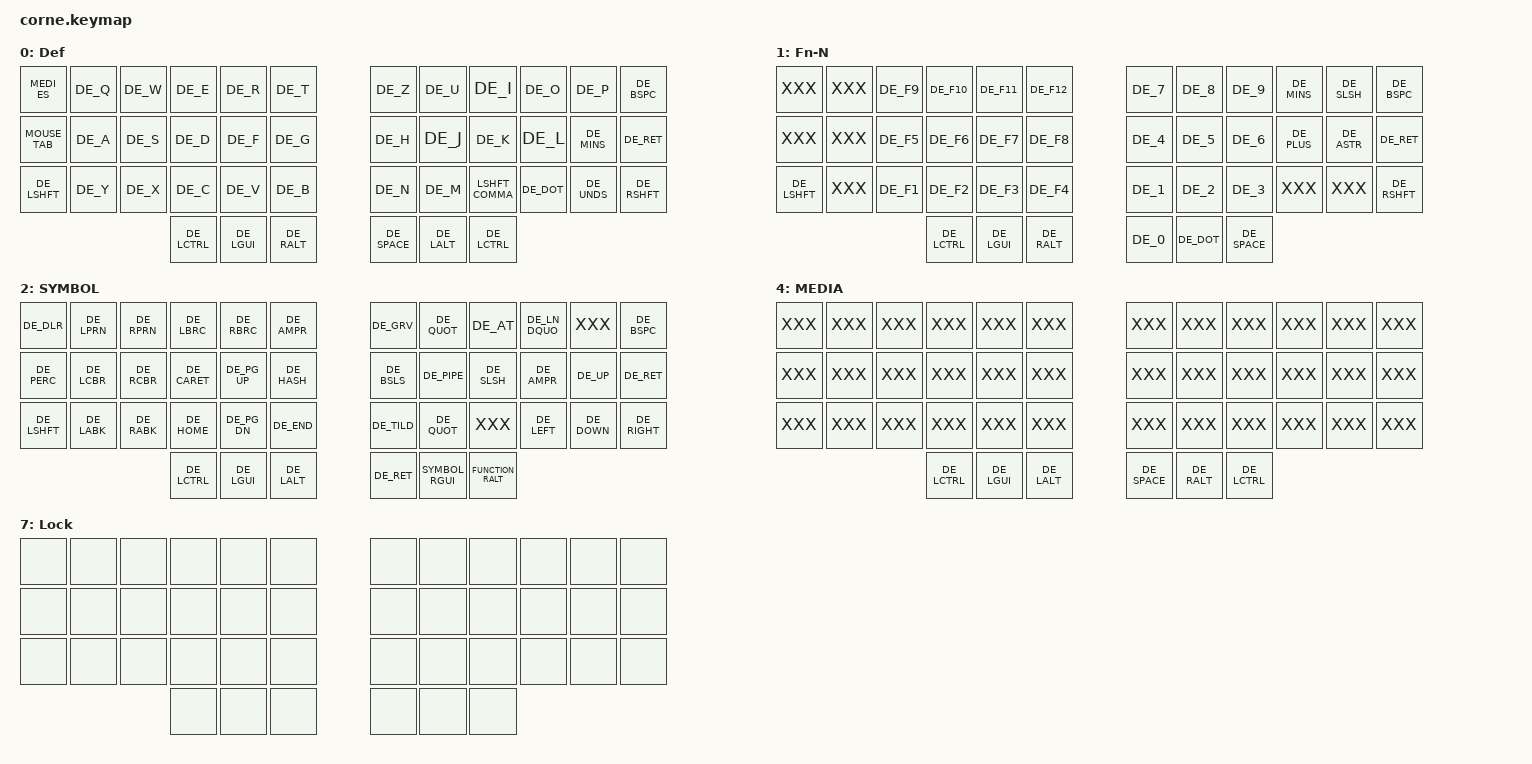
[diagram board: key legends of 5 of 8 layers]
/* ========================================
FileName: corne.keymap
Date: 15:17 23.September.2022
Author: Marcos Chow Castro
Email: mctechnology170318@gmail.com
GitHub: https://github.com/mctechnology17
Brief: keymap for the wireless corne keyboard
                             ╔═╦═╦═╗
                      ╔════╗ ║║║║║╔╝
                      ║╔╗╔╗║ ║║║║║╚╗
                      ╚╝║║╚╝ ║╠═╩╩═╝
                        ║╠═╦═╣╚╦═╦╦═╦╗╔═╦═╦╦╗
                        ║║╩╣═╣║║║║║╬║╚╣╬║╬║║║
                        ╚╩═╩═╩╩╩╩═╩═╩═╩═╬╗╠╗║
                                        ╚═╩═╝
Copyright (c) 2020 The ZMK Contributors
SPDX-License-Identifier: MIT
========================================= */
#define HOST_OS 2
// ### include {{{
#include <behaviors.dtsi>
#include <dt-bindings/zmk/keys.h>
#include <dt-bindings/zmk/bt.h>
#include <dt-bindings/zmk/outputs.h>
#include <dt-bindings/zmk/ext_power.h>
#include <dt-bindings/led/led.h>
#include <dt-bindings/zmk/backlight.h>
#include <dt-bindings/zmk/rgb.h>
#include <dt-bindings/zmk/reset.h>
#include "keymap_german_mac_iso_zmk.h"
#include "keypos_42keys.h"
#include "config_zmk.h"
#include "mouse.dtsi"

&led_strip {
    chain-length = <27>;
};

// }}}
/ {
// ### macros {{{
   macros {
      #include "macros.dtsi"
   };
// }}}

/*                                      42 KEY MATRIX / LAYOUT MAPPING

  ╭────────────────────────┬────────────────────────╮ ╭─────────────────────────┬─────────────────────────╮
  │  0   1   2   3   4   5 │  6   7   8   9  10  11 │ │ LT5 LT4 LT3 LT2 LT1 LT0 │ RT0 RT1 RT2 RT3 RT4 RT5 │
  │ 12  13  14  15  16  17 │ 18  19  20  21  22  23 │ │ LM5 LM4 LM3 LM2 LM1 LM0 │ RM0 RM1 RM2 RM3 RM4 RM5 │
  │ 24  25  26  27  28  29 │ 30  31  32  33  34  35 │ │ LB5 LB4 LB3 LB2 LB1 LB0 │ RB0 RB1 RB2 RB3 RB4 RB5 │
  ╰───────────╮ 36  37  38 │ 39  40  41 ╭───────────╯ ╰───────────╮ LH2 LH1 LH0 │ RH0 RH1 RH2 ╭───────────╯
              ╰────────────┴────────────╯                         ╰─────────────┴─────────────╯             */

// ### combos {{{
combos {
    compatible = "zmk,combos";
    unlock { bindings = <&to DEFAULT>; key-positions = <LT5 LH0 RH0 RT5>; layers = <LOCK>; };
    lock { bindings = <&to LOCK>; key-positions = <LT5 RH0>; layers = <LX_>; };
    CO_symbol { bindings = <&to SYMBOL>; key-positions = <22 23>; layers = <DEFAULT NUMBER MOUSE>; };
    CO_FnN { bindings = <&to NUMBER>; key-positions = <10 11>; layers = <DEFAULT SYMBOL MOUSE>; };
    MO_FnN { bindings = <&mo NUMBER>; key-positions = <0 1>; layers = <DEFAULT SYMBOL MOUSE>; };
    MO_symbol { bindings = <&mo SYMBOL>; key-positions = <12 13>; layers = <DEFAULT NUMBER MOUSE>; };
    CO_Def { bindings = <&to DEFAULT>; key-positions = <34 35>; layers = <SYMBOL NUMBER MOUSE>; };
    CO_Mou { bindings = <&to MOUSE>; key-positions = <6 8>; layers = <DEFAULT SYMBOL NUMBER>; };
    CO_AT { bindings = <&kp LBKT>; key-positions = <39 40 41>; };

    CO_UP { bindings = <&kp UP>; key-positions = <9 21>; };
    CO_LEFT { bindings = <&kp LEFT>; key-positions = <20 21>; };
    CO_DOWN { bindings = <&kp DOWN>; key-positions = <21 33>; };
    CO_RIGHT { bindings = <&kp RIGHT>; key-positions = <21 22>; };

    CO_PAGEUP { bindings = <&kp PG_UP>; key-positions = <10 22>; };
    CO_PAGEDOWN { bindings = <&kp PG_DN>; key-positions = <22 34>; };
    CO_HOME { bindings = <&kp HOME>; key-positions = <8 20>; };
    CO_END { bindings = <&kp END>; key-positions = <20 32>; };

    CO_PreScr { bindings = <&kp PRINTSCREEN>; key-positions = <36 37 38>; };

    CO_F11 { bindings = <&kp F11>; key-positions = <4 5>; };
    CO_F10 { bindings = <&kp F10>; key-positions = <3 4>; };
    CO_F9 { bindings = <&kp F9>; key-positions = <2 3>; };
    CO_F8 { bindings = <&kp F8>; key-positions = <1 2>; };
    CO_F7 { bindings = <&kp F7>; key-positions = <16 17>; };
    CO_F6 { bindings = <&kp F6>; key-positions = <15 16>; };
    CO_F5 { bindings = <&kp F5>; key-positions = <14 15>; };
    CO_F4 { bindings = <&kp F4>; key-positions = <13 14>; };
    CO_F2 { bindings = <&kp F2>; key-positions = <27 28>; };


};
// }}}

// }}}
   // ### conditional_layers {{{
   conditional_layers {
        compatible = "zmk,conditional-layers";

        tri_layer {
            if-layers = <SYMBOL FUNCTION>;
            then-layer = <LX_>;
        };
    };

   //}}}


   keymap {
      compatible = "zmk,keymap";
      // ### default_layer {{{
      default_layer {
      /*.------------------------------------------------.                         .-------------------------------------------------.
         |   ESC  |  Q/!  |  W/"  |  E/#  |  R/$  |  T/%  |                         |  Z/&  |  U/'  |  I/(  |  O/)  |  P/@  | BACKSPC |
         |--------+-------+-------+-------+-------+-------|                         |-------+-------+-------+-------+-------+---------|
         |   TAB  |   A   |   S   |   D   |   F   |   G   |                         |  H/;  |  J/:  |  K/[  |  L/]  |  -/=  |   ENTER |
         |--------+-------+-------+-------+-------+-------|                         |-------+-------+-------+-------+-------+---------|
         |  SHIFT |   Y   |   X   |   C   |   V   |   B   |                         |   N   |   M   |  ,/<  |  ./>  |  _/?  |   SHIFT |
         '---------------------------------------------------------|       |----------------------------------------------------------'
                                  |  CTRL    |  GUI       |   ALT  |       |    SPACE  |    ALT    |   CTRL   |
                                  '--------------------------------'       '----------------------------------'*/
         label = "Def";
         bindings = <
            MEDI_ES     DE_Q       DE_W   DE_E   DE_R      DE_T                            DE_Z        DE_U     DE_I         DE_O     DE_P     DE_BSPC
            MOUSE_TAB   DE_A       DE_S   DE_D   DE_F      DE_G                            DE_H        DE_J     DE_K         DE_L     DE_MINS  DE_RET
            DE_LSHFT    DE_Y       DE_X   DE_C   DE_V      DE_B                            DE_N        DE_M     LSHFT_COMMA  DE_DOT   DE_UNDS  DE_RSHFT
                                                   DE_LCTRL  DE_LGUI  DE_RALT        DE_SPACE  DE_LALT  DE_LCTRL
            >;
      };
      // }}}
      // ### number_layer {{{
      number_layer {
       /*.-------------------------------------------------.                         .-------------------------------------------------.
         |         |       |  F9   |  F10  |   F11 |   F12 |                         |   7   |   8   |   9   |   -   |   /   | BACKSPC |
         |---------+-------+-------+-------+-------+-------|                         |-------+-------+-------+-------+-------+---------|
         |         |       |  F5   |  F6   |   F7  |   F8  |                         |   4   |   5   |   6   |   +   |   *   |   ENTER |
         |---------+-------+-------+-------+-------+-------|                         |-------+-------+-------+-------+-------+---------|
         | SHIFT   |       |  F1   |  F2   |   F3  |   F4  |                         |   1   |   2   |   3   |       |       |   SHIFT |
         '----------------------------------------------------------|       |----------------------------------------------------------'
                                   |  CTRL |  GUI  |       ALT      |       |    0   |   .   |       SPACE   |
                                   '--------------------------------'       '--------------------------------'*/
         label = "Fn-N";
         bindings = <
         XXX       XXX    DE_F9  DE_F10  DE_F11  DE_F12                       DE_7   DE_8   DE_9    DE_MINS  DE_SLSH    DE_BSPC
         XXX       XXX    DE_F5  DE_F6   DE_F7   DE_F8                        DE_4   DE_5   DE_6    DE_PLUS  DE_ASTR    DE_RET
         DE_LSHFT  XXX    DE_F1  DE_F2   DE_F3   DE_F4                        DE_1   DE_2   DE_3    XXX      XXX        DE_RSHFT     
                                         DE_LCTRL  DE_LGUI    DE_RALT    DE_0  DE_DOT   DE_SPACE
            >;
      };
      // }}}
      // ### symbol_layer {{{
      symbol_layer {
       /*.------------------------------------------------.          TODO:          .-------------------------------------------------.
         |   $    |   (   |   )   |   [   |   ]   |   &   |                         |  `    |   '   |   @   |   "   |       |BACKSPC  |
         |--------+-------+-------+-------+-------+-------|                         |-------+-------+-------+-------+-------+---------|
         |   %    |   {   |   }   |   ^   |PAGE_UP|   #   |                         |   \   |   |   |   /   |  &    |  UP   |   ENTER |
         |--------+-------+-------+-------+-------+-------|                         |-------+-------+-------+-------+-------+---------|
         |SHIFT   |    <  |   >   |  HOME |PAGE_DO|  END  |                         |   ~   |   '   |       |  LEFT |  DOWN |   RIGHT |
         '---------------------------------------------------------|       |----------------------------------------------------------'
                                  |  CTRL    |  GUI       |   ALT  |       |  ENTER | SMBOL |          CTRL |
                                  '--------------------------------'       '--------------------------------'*/
         label = "SYMBOL";
         bindings = <
         DE_DLR   DE_LPRN  DE_RPRN   DE_LBRC  DE_RBRC    DE_AMPR                    DE_GRV   DE_QUOT   DE_AT      DE_LN_DQUO  XXX      DE_BSPC
         DE_PERC  DE_LCBR  DE_RCBR   DE_CARET DE_PG_UP   DE_HASH                    DE_BSLS  DE_PIPE   DE_SLSH  DE_AMPR     DE_UP    DE_RET
         DE_LSHFT DE_LABK  DE_RABK   DE_HOME  DE_PG_DN   DE_END                     DE_TILD  DE_QUOT   XXX      DE_LEFT     DE_DOWN  DE_RIGHT
                                              DE_LCTRL   DE_LGUI  DE_LALT  DE_RET  SYMBOL_RGUI  FUNCTION_RALT
         >;
      };
      // }}}
      // ### function_layer {{{
      function_layer {
       /*.------------------------------------------------.                         .-------------------------------------------------.
         |        |       |       |       |       |       |                         |DE_F13 | DE_F14|DE_F15 | DE_F16|       |         |
         |--------+-------+-------+-------+-------+-------|                         |-------+-------+-------+-------+-------+---------|
         |        |       |       |       |       |       |                         |C-A-DEL|DE_F19 |DE_F20 |CLR_LIN|PAGE_UP|         |
         |--------+-------+-------+-------+-------+-------|                         |-------+-------+-------+-------+-------+---------|
         |        |       |       |       |       |       |                         |       |       |       |  HOME |PAGE_DO|    END  |
         '----------------------------------------------------------|       |----------------------------------------------------------'
                                   |  CTRL    |  GUI       |   ALT  |       |  TAB   |   ´   |          CTRL |
                                   '--------------------------------'       '--------------------------------'
         LCTL(LGUI(KC_D)), LCTL(LGUI(KC_SPC))*/
         label = "FUNCTION";
         bindings = <
         XXX       XXX      XXX      XXX     XXX       XXX               &macro6   &macro5   &macro8    &macro2   XXX        XXX
         DE_MINS   DE_NDSH  DE_MDSH  XXX     XXX       XXX               TASKM     &macro1   &macro3    &macro4   DE_PG_UP   &macro9
         XXX       XXX      XXX      XXX     XXX       XXX               XXX       XXX       XXX        DE_HOME   DE_PG_DN   DE_END
                                         DE_LCTRL DE_LGUI  DE_LALT  DE_TAB  DE_ACUT   DE_LCTRL
                              >;
                      };
      // }}}
      // ### media_layer {{{
      media_layer {
       /*.------------------------------------------------.                         .-------------------------------------------------.
         |        |       |       |       |       |       |                         |       |       |       |       |       |         |
         |--------+-------+-------+-------+-------+-------|                         |-------+-------+-------+-------+-------+---------|
         |        |       |       |       |       |       |                         |       |       |       |       |       |         |
         |--------+-------+-------+-------+-------+-------|                         |-------+-------+-------+-------+-------+---------|
         |        |       |       |       |       |       |                         |       |       |       |       |       |         |
         '---------------------------------------------------------|       |----------------------------------------------------------'
                                  |  CTRL    |  GUI       |   ALT  |       |  SPACE | ALTGR |          CTRL |
                                  '--------------------------------'       '--------------------------------'*/
         label = "MEDIA";
         bindings = <
         XXX          XXX      XXX      XXX     XXX       XXX               XXX        XXX       XXX        XXX         XXX        XXX    
         XXX          XXX      XXX      XXX     XXX       XXX               XXX        XXX       XXX        XXX         XXX        XXX    
         XXX          XXX      XXX      XXX     XXX       XXX               XXX        XXX       XXX        XXX         XXX        XXX    
                                        DE_LCTRL  DE_LGUI  DE_LALT  DE_SPACE  DE_RALT DE_LCTRL
                              >;
                      };
      // }}}
      // ### mouse_layer: mouse {{{
      mouse_layer {
       /*.------------------------------------------------.                         .-------------------------------------------------.(dead)
         |WH_LEFT |WH_RIGH|       |       |       |       |                         |       |       |       |       |WH_DOWN| WH_UP   |(dead)
         |--------+-------+-------+-------+-------+-------|                         |-------+-------+-------+-------+-------+---------|(dead)
         |        |CLICK_1|CLICK_2|CLICK_3|BT_PRV | BT_NXT|                         |       |       |       |CLICK_1| UP    |CLICK_2  |(dead)
         |--------+-------+-------+-------+-------+-------|                         |-------+-------+-------+-------+-------+---------|(dead)
         |BT_CLR  |BT_0   |BT_1   |BT_2   |BT_3   |BT_4   |                         |       |       |       | LEFT  | DOWN  | RIGHT   |(dead)
         '---------------------------------------------------------|       |----------------------------------------------------------'(dead)
                                  |        |      |                |       |   MOUSE  |           |        |
                                  '--------------------------------'       '--------------------------------'*/
         label = "MOUSE";
         bindings = <
         SCROLL_LEFT SCROLL_RIGHT XXX         XXX          XXX           XXX                      XXX        XXX       XXX        XXX             SCROLL_DOWN SCROLL_UP
         XXX         CLICK_LEFT   CLICK_RIGHT CLICK_MIDDLE &bt BT_PRV    &bt BT_NXT               XXX        XXX       XXX        CLICK_LEFT      MOVE_UP     CLICK_RIGHT
         &bt BT_CLR  &bt BT(0)    &bt BT(1)   &bt BT(2)    &bt BT(3)     &bt BT(4)                XXX        XXX       XXX        MOVE_LEFT       MOVE_DOWN   MOVE_RIGHT
                                         XXX         XXX        XXX                          MOUSE_TAB    XXX       XXX
                              >;
                      };
      // }}}
      // ### linux_symbol {{{
      linux_symbol {
       /*.------------------------------------------------.          TODO:          .-------------------------------------------------.
         |   $    |   (   |   )   |   [   |   ]   |   &   |                         |  `    |   '   |       |       |       |BACKSPC  |
         |--------+-------+-------+-------+-------+-------|                         |-------+-------+-------+-------+-------+---------|
         |   %    |   {   |   }   |   ^   |PAGE_UP|   #   |                         |    \  |   |   |   /   |   &   |  UP   |   ENTER |
         |--------+-------+-------+-------+-------+-------|                         |-------+-------+-------+-------+-------+---------|
         |SHIFT   |    <  |   >   |  HOME |PAGE_DO|  END  |                         |   ~   |   '   |   @   |  LEFT |  DOWN |   RIGHT |
         '---------------------------------------------------------|       |----------------------------------------------------------'
         DE_LN_DQUO               |DE_F13 |    DE_F14     | DE_F15 |       |  SPACE | ALTGR |          CTRL |
                                  '--------------------------------'       '--------------------------------'*/
         label = "LX_";
         bindings = <
         DE_DLR   DE_LN_LPRN  DE_LN_RPRN   DE_LN_LBRC  DE_LN_RBRC  DE_LN_AMPS                DE_GRV      DE_QUOT     XXX         XXX          XXX            DE_BSPC
         DE_PERC  DE_LN_LCBR  DE_LN_RCBR   DE_LN_CARET DE_PG_UP    DE_HASH                   DE_LN_BSLH  DE_LN_PIPE  DE_LN_FSLH  DE_LN_AMPS  DE_UP       DE_RET
         DE_LSHFT DE_LN_LABK  DE_LN_RABK   DE_HOME     DE_PG_DN    DE_END                    DE_LN_TILDE DE_QUOT     DE_LN_AT    NAV_LEFT    DE_DOWN     NAV_RIGHT
                                              &macro7   &macro5  &macro8  DE_SPACE  DE_RALT  DE_LCTRL
         >;
      };
      // }}}
   // ### lock  {{{
      lock {
         label = "Lock";
         bindings = <
            &none  &none  &none  &none  &none  &none  &none  &none  &none  &none  &none  &none
            &none  &none  &none  &none  &none  &none  &none  &none  &none  &none  &none  &none
            &none  &none  &none  &none  &none  &none  &none  &none  &none  &none  &none  &none
                                 &none  &none  &none  &none  &none  &none
            >;
        };
   //}}}
   };
};

// vim: filetype=dts fdm=marker:
